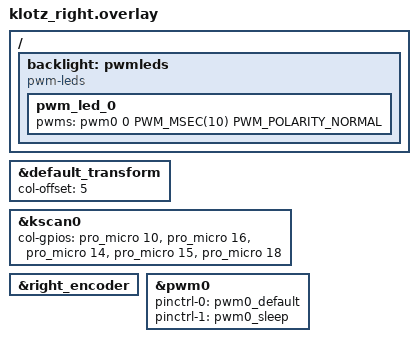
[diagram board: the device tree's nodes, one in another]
/*
 * Copyright (c) 2020 Pete Johanson
 *
 * SPDX-License-Identifier: MIT
 */

#include "klotz.dtsi"

&default_transform {
	col-offset = <5>;
};

&kscan0 {
	col-gpios
		= <&pro_micro 10 GPIO_ACTIVE_HIGH>
		, <&pro_micro 16 GPIO_ACTIVE_HIGH>
		, <&pro_micro 14 GPIO_ACTIVE_HIGH>
		, <&pro_micro 15 GPIO_ACTIVE_HIGH>
		, <&pro_micro 18 GPIO_ACTIVE_HIGH>
		;
};

&right_encoder {
	status = "okay";
};

&pwm0 {
    status = "okay";
    pinctrl-0 = <&pwm0_default>;
    pinctrl-1 = <&pwm0_sleep>;
    pinctrl-names = "default", "sleep";
};

/ {
    backlight: pwmleds {
        compatible = "pwm-leds";
        pwm_led_0 {
            pwms = <&pwm0 0 PWM_MSEC(10) PWM_POLARITY_NORMAL>;
        };
    };
};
